# MDR1986VE4 register map
Vendor: Milandr; Series: ARMCM0; File version: 2.0
CPU: CM0 r0p0, little endian, no MPU, no FPU, 2 interrupt priority bits
Registers are 32-bit, read-write, reset 0x0 unless marked. A register's access mark holds for its fields unless they carry their own. Offsets are from the block's base; [hi:lo] are bit positions; {n}, {i} and the like mark numbered series.

## MDR_Power — Power Detector
Base 0x40058000
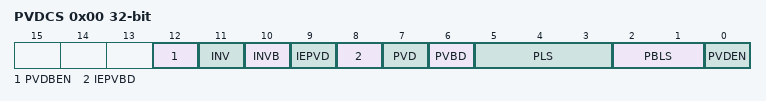
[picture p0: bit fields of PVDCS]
0x00 PVDCS — Control-Status register
  [12] PVDBEN — Enable BUcc detector
    0=Off (Disabled); 1=On (Enabled)
  [11] INV — PVD event on BUcc lt PBLS
    0=Off (Disabled); 1=On (Enabled)
  [10] INVB — PVBD event on BUcc lt PBLS
    0=Off (Disabled); 1=On (Enabled)
  [9] IEPVD — Enable IRQ by PVD event
    0=Off (Disabled); 1=On (Enabled)
  [8] IEPVBD — Enable IRQ by PVBD event
    0=Off (Disabled); 1=On (Enabled)
  [7] PVD — Event on Ucc gt PLS
    0=Inactive (No Event); 1=Active (Event is active)
  [6] PVBD — Event on BUcc gt PBLS
    0=Inactive (No Event); 1=Active (Event is active)
  [5:3] PLS — Ucc compare level
    0=2v0 (Level of 2.0 volts); 1=2v2 (Level of 2.2 volts); 2=2v4 (Level of 2.4 volts); 3=2v6 (Level of 2.6 volts); 4=2v8 (Level of 2.8 volts); 5=3v0 (Level of 3.0 volts); 6=3v2 (Level of 3.2 volts); 7=3v4 (Level of 3.4 volts)
  [2:1] PBLS — BUcc compare level
    0=1v8 (Level of 1.8 volts); 1=2v2 (Level of 2.2 volts); 2=2v6 (Level of 2.6 volts); 3=3v0 (Level of 3.0 volts)
  [0] PVDEN — Enable Ucc detector
    0=Off (Disabled); 1=On (Enabled)
0x04 ResReg ro reset not defined — Reserved register
  [31:0] Value — blank

## MDR_WWDT — Window Watchdog Timer
Base 0x40048000
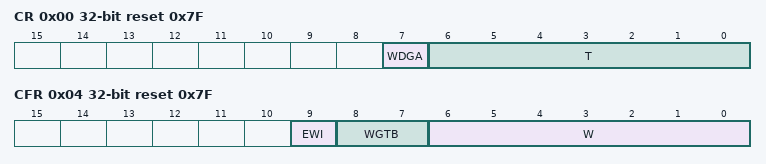
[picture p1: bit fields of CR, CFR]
0x00 CR reset 0x7F — WWDT Control register
  [7] WDGA — Enable
    0=Off (Disabled); 1=On (Enabled)
  [6:0] T — Counter
0x04 CFR reset 0x7F — WWDT Config register
  [9] EWI — Early Window Interrupt
    0=Off (Disabled IRQ on T=0x40); 1=On (Enabled IRQ on T=0x40)
  [8:7] WGTB — Clock Divider
    0=div1 (CLK = LSI/4096/1); 1=div2 (CLK = LSI/4096/2); 2=div4 (CLK = LSI/4096/4); 3=div8 (CLK = LSI/4096/8)
  [6:0] W — Window value
0x08 SR — WWDT Status register
  [0] EWIF — Early Window Flag
    0=Off (Event Off); 1=Onn (Event On)

## MDR_IWDT — Independent Watchdog Timer
Base 0x40050000
0x00 KR wo — Key register
  [15:0] KEY — Enable, start and reload control
0x04 PR — Clock Prescaler register
  [2:0] PR — Prescaler Register
    0=div4 (LSI div 4); 1=div8 (LSI div 8); 2=div16 (LSI div 16); 3=div32 (LSI div 32); 4=div64 (LSI div 64); 5=div128 (LSI div 128); 6=div256 (LSI div 256); 7=div256_1 (LSI div 256)
0x08 RLR reset 0xFFF — Reload Period Register
  [11:0] PRL — Timer Period Value
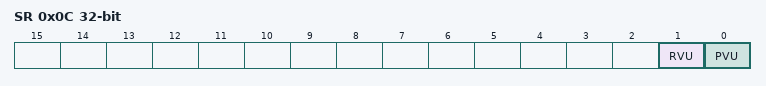
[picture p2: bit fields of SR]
0x0C SR ro — Status Regster
  [1] RVU — PRL busy
    0=Ready (PRL ready for write); 1=Busy (PRL busy)
  [0] PVU — PR busy
    0=Ready (PR ready for write); 1=Busy (PR busy)

## MDR_ADCUI — Energy Counter Block
Base 0x40068000
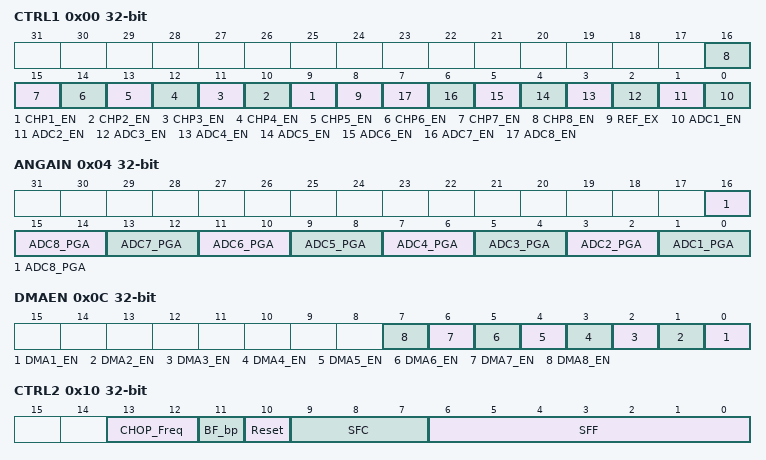
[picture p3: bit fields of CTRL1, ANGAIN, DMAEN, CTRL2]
0x00 CTRL1 — ADCUI Control1 Register
  [n+8] CHP{n}_EN (n=1..8) — Exclude constant component
    0=ConstOn (With const level); 1=ConstOff (Exclute const level)
  [8] REF_EX — Select VRef
    0=Internal 1.2V; 1=External 1.2V from pin VR_1V
  [n-1] ADC{n}_EN (n=1..8) — Channel enable
    0=Off (Disabled); 1=On (Enabled)
0x04 ANGAIN (reset mask 0xFFFF) — Analog Amplifier Control
  [all] fields
    0=Gain 0dB; 1=x4 (Gain 12dB); 2=x2 (Gain 6dB); 3=x16 (Gain 24dB)
  [16:14] ADC8_PGA — Gain Select
  [2n-1:2n-2] ADC{n}_PGA (n=1..7) — Gain Select
0x08 DIGGAIN ro reset 0x2A (reset mask 0x2A) — Digital Amplifier Control
0x0C DMAEN — DMA Request Control
  [all] fields
    0=Off (Disable); 1=On (Enable)
  [n-1] DMA{n}_EN (n=1..8) — DMA Request Enable
0x10 CTRL2 (reset mask 0x3FF) — ADCUI Control2 Register
  [13:12] CHOP_Freq — Chopper frequency
    0=Invalid_0 (Invalid value); 1=Invalid_1 (Invalid value); 2=Invalid_2 (Invalid value); 3=Ok (Default value)
  [11] BF_bp — Avoid Vref buffer
    0=BuffOn (Buffer used); 1=ByPass (Buffer by pass)
  [10] Reset — Digital part reset
    0=Working state; 1=DigInReset (Digital control in reset)
  [9:7] SFC — Sinc Filter Rough correction
    {v}=cor_{v} (Correction) (v=0..7)
  [6:0] SFF — Sinc Filter Fine correction
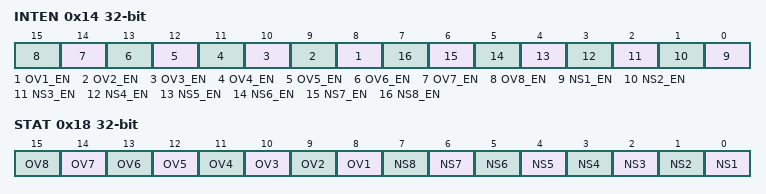
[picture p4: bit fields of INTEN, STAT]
0x14 INTEN — Irq Enable Control
  [all] fields
    0=Off (Disable); 1=On (Enable)
  [n+7] OV{n}_EN (n=1..8) — IRQ by Override ready
  [n-1] NS{n}_EN (n=1..8) — IRQ by ADC ready
0x18 STAT — Status Register
  [all] fields
    0=Off (Disable); 1=On (Enable)
  [n+7] OV{n} (n=1..8) — FIFO Override event
  [n-1] NS{n} (n=1..8) — ADC ready event
{0x18+4i} ADC{i}_DAT (i=1..8) ro (reset mask 0xFFFFFF) — ADC FIFO read
0x3C TST — Test register
  [1] TST2 — Vref to pin VR_1V
    0=Invalid Value; 1=On (Connected)
